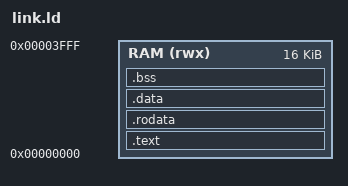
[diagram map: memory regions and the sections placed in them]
ENTRY(_start)
MEMORY { RAM (rwx) : ORIGIN = 0, LENGTH = 16K }
SECTIONS {
    .text : { KEEP(*(.text.start)) *(.text*) } > RAM
    .rodata : { *(.rodata*) } > RAM
    .data : { *(.data*) *(.sdata*) } > RAM
    .bss (NOLOAD) : {
        . = ALIGN(4); __bss_start = .;
        *(.bss*) *(.sbss*) *(COMMON)
        . = ALIGN(4); __bss_end = .;
    } > RAM
    __stack_top = ORIGIN(RAM) + LENGTH(RAM);
    ASSERT(__bss_end < __stack_top - 2048, "Insufficient stack space")
}
